# STM32F413CGU3 register map
File version: 1.0
Registers are 32-bit, access not given, reset 0x0 unless marked. A register's access mark holds for its fields unless they carry their own. Offsets are from the block's base; [hi:lo] are bit positions; {n}, {i} and the like mark numbered series; 'fields as' and 'values as' point back to an identical list.

## TIM6
Base 0x40001000
Same registers: TIM7 0x40001400
0x00 CR1
0x04 CR2
0x0C DIER
0x10 SR
0x14 EGR
0x24 CNT
0x28 PSC
0x2C ARR

## TIM12
Base 0x40001800
Same registers: TIM9 0x40014000
0x00 CR1
  [9:8] CKD, [7] ARPE, [31:4] s, [3] OPM, [2] URS, [1] UDIS, [0] CEN
0x08 SMCR
  [7] MSM, [6:4] TS, [31:3] s, [2:0] SMS
0x0C DIER
  [6] TIE, [31:3] s, [2] CC2IE, [1] CC1IE, [0] UIE
0x10 SR
  [10] CC2OF, [9] CC1OF, [6] TIF, [31:3] s, [2] CC2IF, [1] CC1IF, [0] UIF
0x14 EGR
  [6] TG, [31:3] s, [2] CC2G, [1] CC1G, [0] UG
0x18 CCMR1_OUT
  [14:12] OC2M, [11] OC2PE, [10] OC2FE, [9:8] CC2S, [31:7] s, [6:4] OC1M, [3] OC1PE, [2] OC1FE, [1:0] CC1S
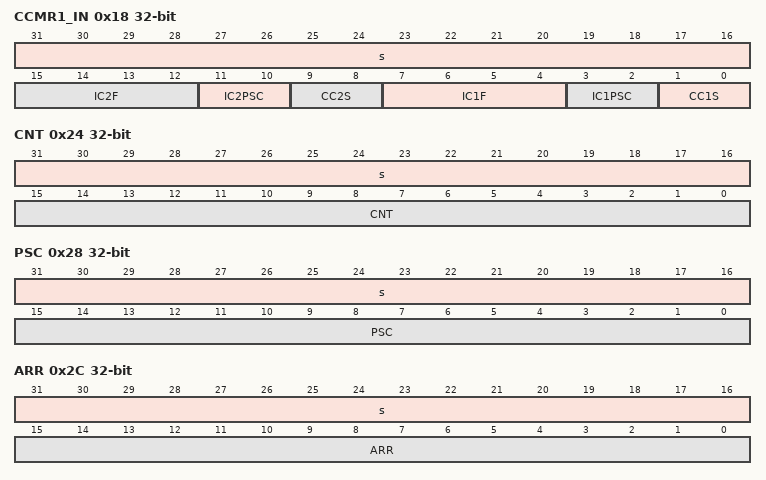
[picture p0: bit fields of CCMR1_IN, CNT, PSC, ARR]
0x18 CCMR1_IN
  [31:16] s, [15:12] IC2F, [11:10] IC2PSC, [9:8] CC2S, [7:4] IC1F, [3:2] IC1PSC, [1:0] CC1S
0x20 CCER
  [7] CC2NP, [5] CC2P, [4] CC2E, [3] CC1NP, [31:2] s, [1] CC1P, [0] CC1E
0x24 CNT
  [31:16] s, [15:0] CNT
0x28 PSC
  [31:16] s, [15:0] PSC
0x2C ARR
  [31:16] s, [15:0] ARR
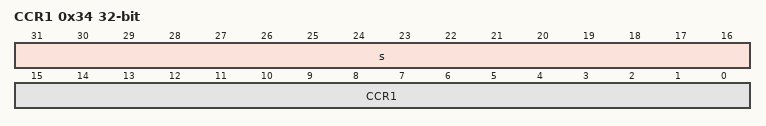
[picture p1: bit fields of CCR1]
0x34 CCR1
  [31:16] s, [15:0] CCR1
0x38 CCR2

## TIM13
Base 0x40001C00
Same registers: TIM14 0x40002000, TIM10 0x40014400, TIM11 0x40014800
0x00 CR1
  [9:8] CKD, [7] ARPE, [31:3] s, [2] URS, [1] UDIS, [0] CEN
0x08 SMCR
  [31:0] s
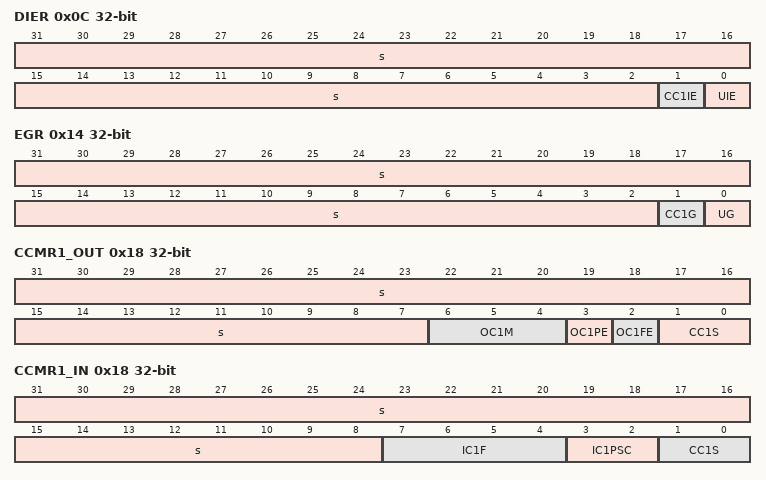
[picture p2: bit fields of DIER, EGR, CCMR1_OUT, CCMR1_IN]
0x0C DIER
  [31:2] s, [1] CC1IE, [0] UIE
0x10 SR
  [9] CC1OF, [31:2] s, [1] CC1IF, [0] UIF
0x14 EGR
  [31:2] s, [1] CC1G, [0] UG
0x18 CCMR1_OUT
  [31:7] s, [6:4] OC1M, [3] OC1PE, [2] OC1FE, [1:0] CC1S
0x18 CCMR1_IN
  [31:8] s, [7:4] IC1F, [3:2] IC1PSC, [1:0] CC1S
0x20 CCER
  [3] CC1NP, [31:2] s, [1] CC1P, [0] CC1E
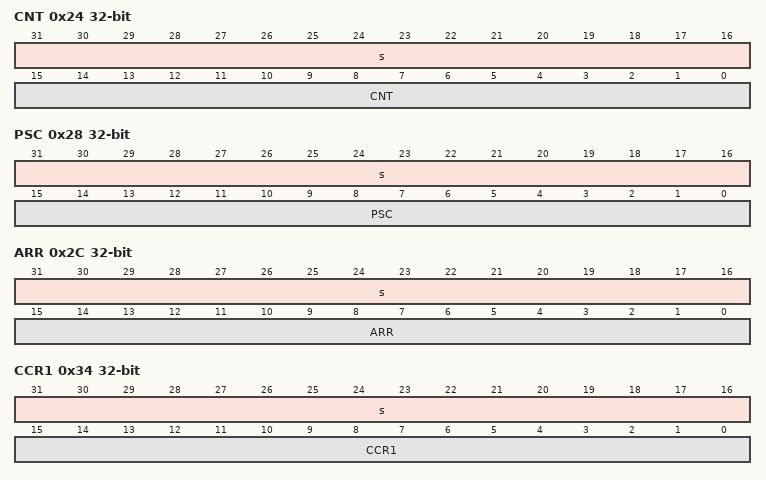
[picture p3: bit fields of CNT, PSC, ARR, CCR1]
0x24 CNT
  [31:16] s, [15:0] CNT
0x28 PSC
  [31:16] s, [15:0] PSC
0x2C ARR
  [31:16] s, [15:0] ARR
0x34 CCR1
  [31:16] s, [15:0] CCR1
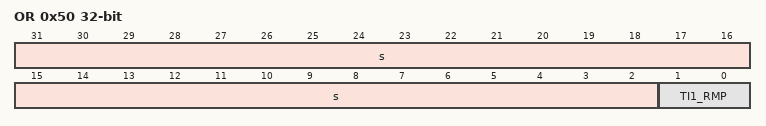
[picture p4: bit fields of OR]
0x50 OR
  [31:2] s, [1:0] TI1_RMP

## LPTIM1
Base 0x40002400
Same registers: TIM1 0x40010000, TIM8 0x40010400
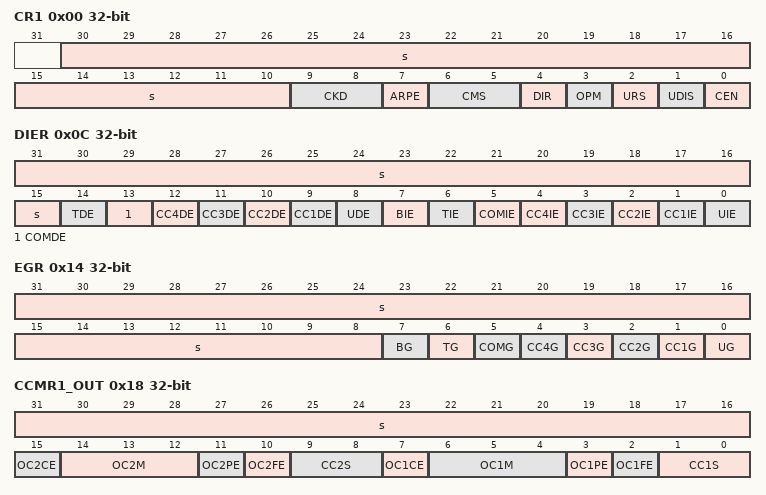
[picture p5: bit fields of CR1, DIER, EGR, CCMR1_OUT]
0x00 CR1
  [30:10] s, [9:8] CKD, [7] ARPE, [6:5] CMS, [4] DIR, [3] OPM, [2] URS, [1] UDIS, [0] CEN
0x04 CR2
  [2n+6] OIS{n} (n=1..4), [13] OIS3N, [11] OIS2N, [9] OIS1N, [7] TI1S, [6:4] MMS, [3] CCDS, [2] CCUS, [31:1] s, [0] CCPC
0x08 SMCR
  [15] ETP, [14] ECE, [13:12] ETPS, [11:8] ETF, [7] MSM, [6:4] TS, [31:3] s, [2:0] SMS
0x0C DIER
  [31:15] s, [14] TDE, [13] COMDE, [n+8] CC{n}DE (n=1..4), [8] UDE, [7] BIE, [6] TIE, [5] COMIE, [n] CC{n}IE (n=1..4), [0] UIE
0x10 SR
  [n+8] CC{n}OF (n=1..4), [31:8] s, [7] BIF, [6] TIF, [5] COMIF, [n] CC{n}IF (n=1..4), [0] UIF
0x14 EGR
  [31:8] s, [7] BG, [6] TG, [5] COMG, [n] CC{n}G (n=1..4), [0] UG
0x18 CCMR1_OUT
  [31:16] s, [15] OC2CE, [14:12] OC2M, [11] OC2PE, [10] OC2FE, [9:8] CC2S, [7] OC1CE, [6:4] OC1M, [3] OC1PE, [2] OC1FE, [1:0] CC1S
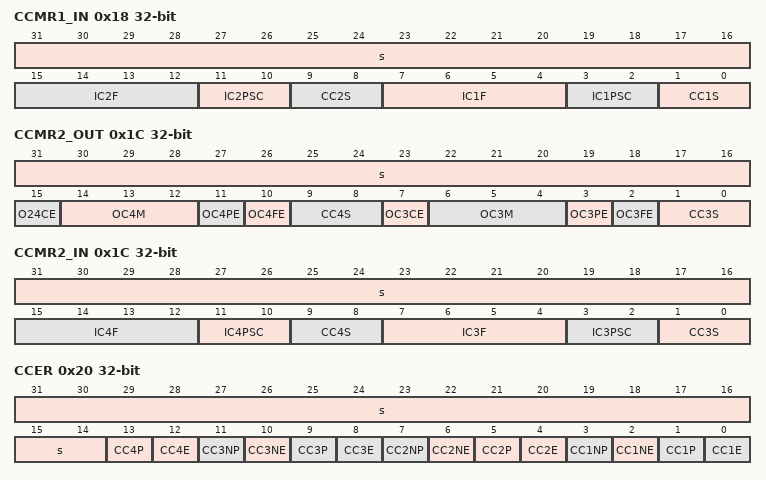
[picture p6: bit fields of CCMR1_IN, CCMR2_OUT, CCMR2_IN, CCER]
0x18 CCMR1_IN
  [31:16] s, [15:12] IC2F, [11:10] IC2PSC, [9:8] CC2S, [7:4] IC1F, [3:2] IC1PSC, [1:0] CC1S
0x1C CCMR2_OUT
  [31:16] s, [15] O24CE, [14:12] OC4M, [11] OC4PE, [10] OC4FE, [9:8] CC4S, [7] OC3CE, [6:4] OC3M, [3] OC3PE, [2] OC3FE, [1:0] CC3S
0x1C CCMR2_IN
  [31:16] s, [15:12] IC4F, [11:10] IC4PSC, [9:8] CC4S, [7:4] IC3F, [3:2] IC3PSC, [1:0] CC3S
0x20 CCER
  [31:14] s, [4n-3] CC{n}P (n=1..4), [4n-4] CC{n}E (n=1..4), [11] CC3NP, [10] CC3NE, [7] CC2NP, [6] CC2NE, [3] CC1NP, [2] CC1NE
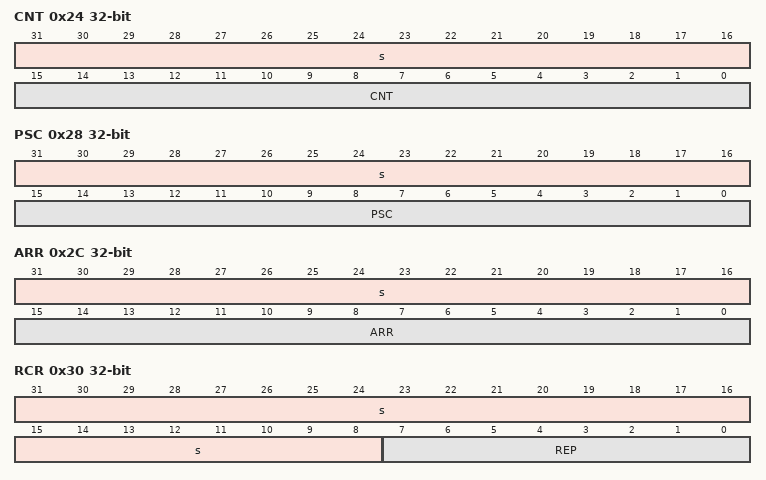
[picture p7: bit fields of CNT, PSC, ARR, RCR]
0x24 CNT
  [31:16] s, [15:0] CNT
0x28 PSC
  [31:16] s, [15:0] PSC
0x2C ARR
  [31:16] s, [15:0] ARR
0x30 RCR
  [31:8] s, [7:0] REP
0x34 CCR1
  [15:0] CCR1
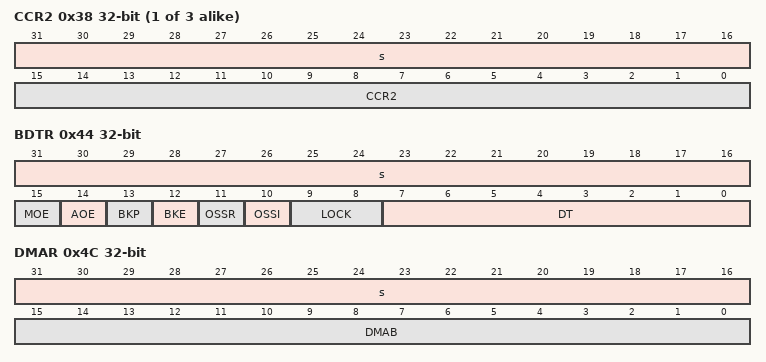
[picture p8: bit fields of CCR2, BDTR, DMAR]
{0x30+4i} CCR{i} (i=2..4)
  [31:16] s, [15:0] CCR{i}
0x44 BDTR
  [31:16] s, [15] MOE, [14] AOE, [13] BKP, [12] BKE, [11] OSSR, [10] OSSI, [9:8] LOCK, [7:0] DT
0x48 DCR
  [12:8] DBL, [31:5] s, [4:0] DBA
0x4C DMAR
  [31:16] s, [15:0] DMAB

## RTC
Base 0x40002800
0x00 TR
  [22] PM, [21:20] HT, [19:16] HU, [14:12] MNT, [11:8] MNU, [31:7] s, [6:4] ST, [3:0] SU
0x04 DR
  [23:20] YT, [19:16] YU, [15:13] WDU, [12] MT, [11:8] MU, [31:6] s, [5:4] DT, [3:0] DU
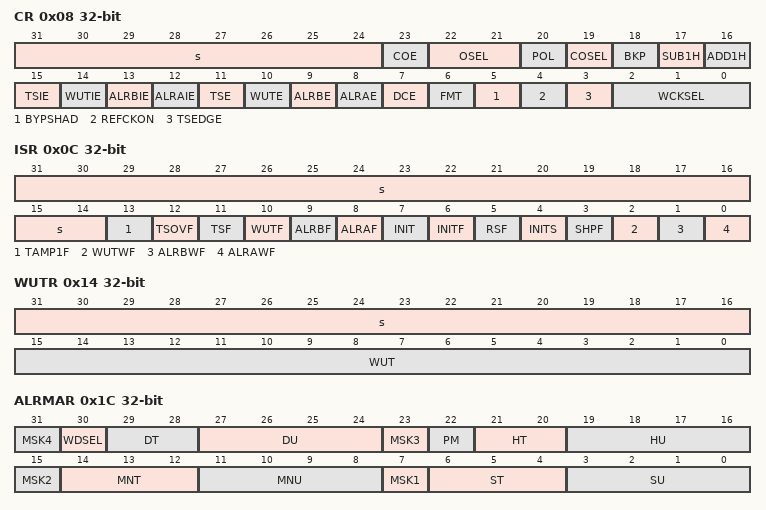
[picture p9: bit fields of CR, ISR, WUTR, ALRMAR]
0x08 CR
  [31:24] s, [23] COE, [22:21] OSEL, [20] POL, [19] COSEL, [18] BKP, [17] SUB1H, [16] ADD1H, [15] TSIE, [14] WUTIE, [13] ALRBIE, [12] ALRAIE, [11] TSE, [10] WUTE, [9] ALRBE, [8] ALRAE, [7] DCE, [6] FMT, [5] BYPSHAD, [4] REFCKON, [3] TSEDGE, [2:0] WCKSEL
0x0C ISR
  [31:14] s, [13] TAMP1F, [12] TSOVF, [11] TSF, [10] WUTF, [9] ALRBF, [8] ALRAF, [7] INIT, [6] INITF, [5] RSF, [4] INITS, [3] SHPF, [2] WUTWF, [1] ALRBWF, [0] ALRAWF
0x10 PRER
  [22:16] PREDIV_A, [31:15] s, [14:0] PREDIV_S
0x14 WUTR
  [31:16] s, [15:0] WUT
0x18 CALIBR
  [7] DCS, [31:5] s, [4:0] DC
0x1C ALRMAR
  [8n-1] MSK{n} (n=1..4), [30] WDSEL, [29:28] DT, [27:24] DU, [22] PM, [21:20] HT, [19:16] HU, [14:12] MNT, [11:8] MNU, [6:4] ST, [3:0] SU
0x20 ALRMBR
  [31] MSK4, [30] WDSEL, [29:28] DT, [27:24] DU, [23] MSK3, [22] PM, [21:20] HT, [19:16] HU, [14:12] MNT, [11:8] MNU, [15:7] MSK2, [6:4] ST, [3:0] SU
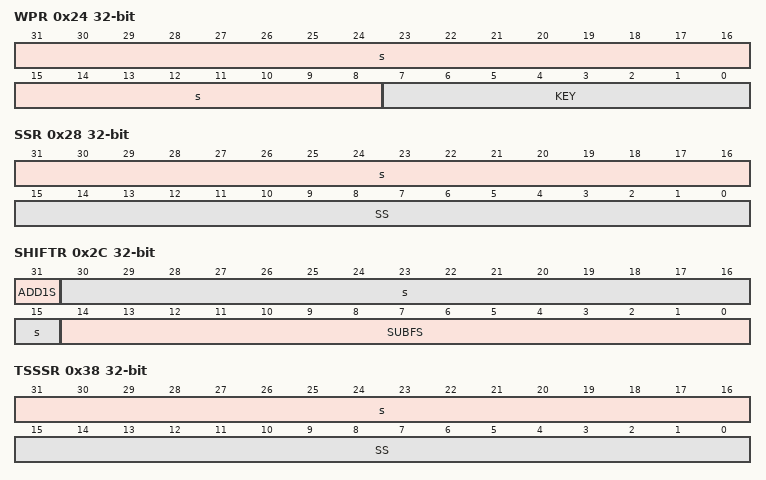
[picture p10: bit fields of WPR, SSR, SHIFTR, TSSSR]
0x24 WPR
  [31:8] s, [7:0] KEY
0x28 SSR
  [31:16] s, [15:0] SS
0x2C SHIFTR
  [31] ADD1S, [30:15] s, [14:0] SUBFS
0x30 TSTR
  fields as TR
0x38 TSSSR
  [31:16] s, [15:0] SS
0x3C CALR
  [15] CALP, [14] CALW8, [13] CALW16, [31:9] s, [8:0] CALM
0x40 TAFCR
  [18] ALARMOUTTYPE, [17] TSINSEL, [16] TAMP1INSEL, [15] TAMPPUDIS, [14:13] TAMPPRCH, [12:11] TAMPFLT, [10:8] TAMPFREQ, [7] TAMPTS, [31:3] s, [2] TAMPIE, [1] TAMP1ETRG, [0] TAMP1E
0x44 ALRMASSR
  [27:24] MASKSS, [31:15] s, [14:0] SS
0x48 ALRMBSSR
  [27:24] MASKSS, [31:15] s, [14:0] SS
{0x50+4i} BKP{i}R (i=0..19)
  [31:0] BKP

## BKP
Base 0x40002800
Registers as RTC; these are added or differ:
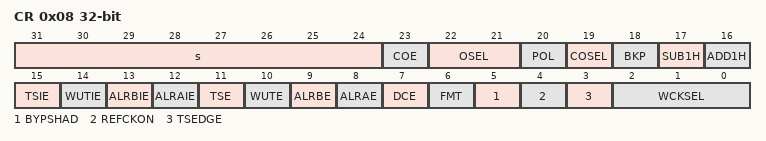
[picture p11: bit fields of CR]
0x08 CR
  fields as RTC.CR
{0x50+4i} BKP{i}R (i=0..19)
  [31:0] BKP
